VERSION ""

NS_ :

BS_:

BU_: ECU

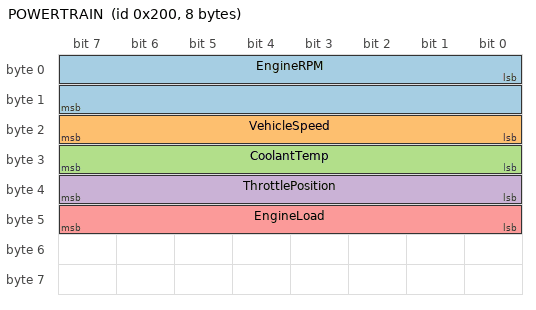
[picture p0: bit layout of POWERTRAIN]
BO_ 512 POWERTRAIN: 8 ECU
 SG_ EngineRPM : 0|16@1+ (0.25,0) [0|16383.75] "rpm" Vector__XXX
 SG_ VehicleSpeed : 16|8@1+ (1,0) [0|255] "km/h" Vector__XXX
 SG_ CoolantTemp : 24|8@1+ (1,-40) [-40|215] "degC" Vector__XXX
 SG_ ThrottlePosition : 32|8@1+ (0.392157,0) [0|100] "%" Vector__XXX
 SG_ EngineLoad : 40|8@1+ (0.392157,0) [0|100] "%" Vector__XXX

CM_ BO_ 512 "Generic powertrain broadcast, a neutral reference for wiring up decode. Not vehicle-specific.";
CM_ SG_ 512 EngineRPM "Engine speed.";
CM_ SG_ 512 VehicleSpeed "Road speed.";
CM_ SG_ 512 CoolantTemp "Engine coolant temperature.";
CM_ SG_ 512 ThrottlePosition "Throttle pedal position.";
CM_ SG_ 512 EngineLoad "Calculated engine load.";
